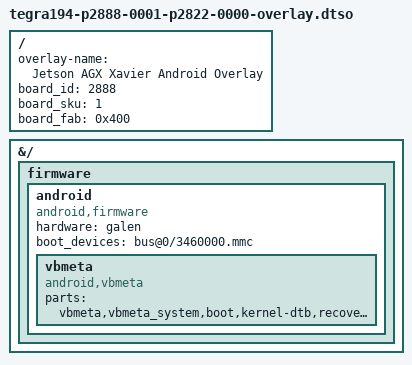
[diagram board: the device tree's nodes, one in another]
/dts-v1/;
/plugin/;

#include "tegra194-lineage.dtsi"

/ {
        overlay-name = "Jetson AGX Xavier Android Overlay";
        board_id = <2888>;
        board_sku = <1>;
        board_fab = <0x400>;
};

&{/} {
	firmware {
		android {
			compatible = "android,firmware";
			hardware = "galen";
			boot_devices = "bus@0/3460000.mmc";
			vbmeta {
				compatible = "android,vbmeta";
				parts = "vbmeta,vbmeta_system,boot,kernel-dtb,recovery";
			};
		};
	};
};
